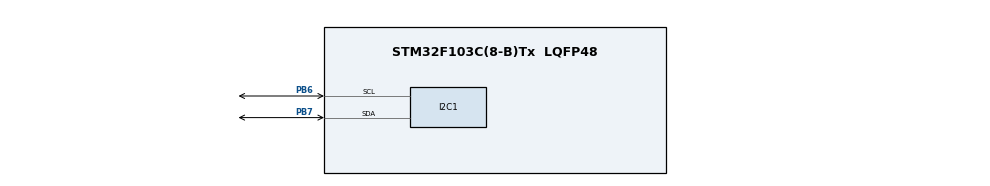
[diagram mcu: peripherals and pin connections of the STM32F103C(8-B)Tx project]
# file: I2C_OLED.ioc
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Mcu.Family=STM32F1
Mcu.Name=STM32F103C(8-B)Tx
Mcu.Package=LQFP48
NVIC.PriorityGroup=NVIC_PRIORITYGROUP_4
PA13.Mode=Serial_Wire
PA13.Signal=SYS_JTMS-SWDIO
PA14.Mode=Serial_Wire
PA14.Signal=SYS_JTCK-SWCLK
PB6.Mode=I2C
PB6.Signal=I2C1_SCL
PB7.Mode=I2C
PB7.Signal=I2C1_SDA
PD0-OSC_IN.Mode=HSE-External-Oscillator
PD0-OSC_IN.Signal=RCC_OSC_IN
PD1-OSC_OUT.Mode=HSE-External-Oscillator
PD1-OSC_OUT.Signal=RCC_OSC_OUT
ProjectManager.HeapSize=0x200
ProjectManager.StackSize=0x400
ProjectManager.TargetToolchain=MDK-ARM V5.32
RCC.APB1Freq_Value=8000000
RCC.APB2Freq_Value=8000000
board=custom

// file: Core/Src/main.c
/* USER CODE BEGIN Header */
/**
  ******************************************************************************
  * @file           : main.c
  * @brief          : Main program body
  ******************************************************************************
  * @attention
  *
  * Copyright (c) 2023 STMicroelectronics.
  * All rights reserved.
  *
  * This software is licensed under terms that can be found in the LICENSE file
  * in the root directory of this software component.
  * If no LICENSE file comes with this software, it is provided AS-IS.
  *
  ******************************************************************************
  */
/* USER CODE END Header */
#include "main.h"
#include "i2c.h"
#include "gpio.h"

/* USER CODE BEGIN Includes */
#include "oled.h"
/* USER CODE END Includes */

/* USER CODE BEGIN PV */
void showString(){
  int x_p=0;
      for (int i=0;i<7;i++){
        OLED_ShowCHinese(x_p,0,i);
        x_p+=18;
      }
}
// 每个滚动步骤之间的时间间隔，以帧为单位，越大越慢
typedef enum
{
	FRAME_2 = 0x07,
	FRAME_3 = 0x04,
	FRAME_4 = 0x05,
	FRAME_5 = 0x06,
	FRAME_6 = 0x00,
	FRAME_32 = 0x01,
	FRAME_64 = 0x02,
	FRAME_128 = 0x03,
}Roll_Frame;

/**
  * @brief  OLED_Inside_Hor_Sroll，内部设置水平滚动
  * @param  start_page,end_page :起始滚动页与终止滚动页(start_page:0~7, end_page:0~7);
  *			frame : 每个滚动步骤之间的时间间隔，以帧为单位，越大越慢(FRAME_2 ~ FRAME_128)
  *			dir : 1 向右水平滚动，0 向左水平滚动
  * @retval 无
  */
void OLED_Inside_Hor_Sroll(uint8_t start_page,uint8_t end_page,Roll_Frame frame,uint8_t dir)
{
	// 先必须关闭滚动
	OLED_WR_CMD(0x2E);

	// 1是向右水平滚动，0是向左水平滚动
	OLED_WR_CMD(dir ? 0x26 : 0x27);

	// 发送一个虚拟字节
	OLED_WR_CMD(0x00);

	OLED_WR_CMD(start_page & 0x07);      //起始页 0
	OLED_WR_CMD(frame & 0x07);           //滚动时间间隔
	OLED_WR_CMD(end_page & 0x07);        //终止页 7

	// 发送两个虚拟字节
	OLED_WR_CMD(0x00);
	OLED_WR_CMD(0xFF);

	//开启滚动
	OLED_WR_CMD(0x2F);
}
/* USER CODE END PV */

void SystemClock_Config(void);

int main(void)
{

  /* MCU Configuration--------------------------------------------------------*/

  /* Reset of all peripherals, Initializes the Flash interface and the Systick. */
  HAL_Init();

  /* Configure the system clock */
  SystemClock_Config();

  /* Initialize all configured peripherals */
  MX_GPIO_Init();
  MX_I2C1_Init();
	OLED_Init();
	OLED_Clear();
  /* USER CODE BEGIN 2 */
    showString();
  OLED_Inside_Hor_Sroll(0,7,FRAME_6,0);

  /* USER CODE END 2 */
  /* Infinite loop */
  /* USER CODE BEGIN WHILE */
  while (1)
  {

  }
}

void SystemClock_Config(void)
{
  RCC_OscInitTypeDef RCC_OscInitStruct = {0};
  RCC_ClkInitTypeDef RCC_ClkInitStruct = {0};

  /** Initializes the RCC Oscillators according to the specified parameters
  * in the RCC_OscInitTypeDef structure.
  */
  RCC_OscInitStruct.OscillatorType = RCC_OSCILLATORTYPE_HSI;
  RCC_OscInitStruct.HSIState = RCC_HSI_ON;
  RCC_OscInitStruct.HSICalibrationValue = RCC_HSICALIBRATION_DEFAULT;
  RCC_OscInitStruct.PLL.PLLState = RCC_PLL_NONE;
  if (HAL_RCC_OscConfig(&RCC_OscInitStruct) != HAL_OK)
  {
    Error_Handler();
  }

  /** Initializes the CPU, AHB and APB buses clocks
  */
  RCC_ClkInitStruct.ClockType = RCC_CLOCKTYPE_HCLK|RCC_CLOCKTYPE_SYSCLK
                              |RCC_CLOCKTYPE_PCLK1|RCC_CLOCKTYPE_PCLK2;
  RCC_ClkInitStruct.SYSCLKSource = RCC_SYSCLKSOURCE_HSI;
  RCC_ClkInitStruct.AHBCLKDivider = RCC_SYSCLK_DIV1;
  RCC_ClkInitStruct.APB1CLKDivider = RCC_HCLK_DIV1;
  RCC_ClkInitStruct.APB2CLKDivider = RCC_HCLK_DIV1;

  if (HAL_RCC_ClockConfig(&RCC_ClkInitStruct, FLASH_LATENCY_0) != HAL_OK)
  {
    Error_Handler();
  }
}

void Error_Handler(void)
{
  __disable_irq();
  while (1)
  {
  }
}
